# trimsir_me12 register map
Registers are read-write, no defined reset value unless marked. A register's access mark holds for its fields unless they carry their own. Offsets are from the block's base; lines under a group give offsets from that group; [hi:lo] are bit positions; {n}, {i} and the like mark numbered series; 'fields as' and 'values as' point back to an identical list; <NAME> marks a mode.

## Memory map
0x40005400 TRIMSIR size 0x400 — Trim System Initilazation Registers

## TRIMSIR — Trim System Initilazation Registers
Base 0x40005400
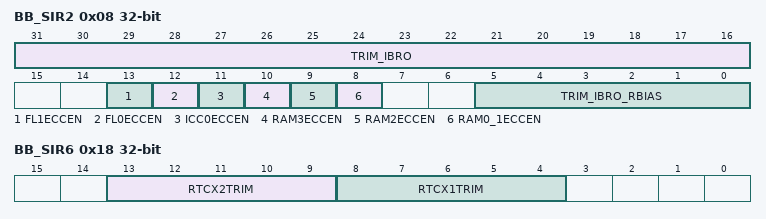
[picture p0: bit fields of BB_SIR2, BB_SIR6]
0x08 BB_SIR2 — System Init. Configuration Register 2.
  [31:16] TRIM_IBRO — HIRC8M Trim
  [13] FL1ECCEN — Flash 1 ECC Enable
    0=dis (ECC Disabled.); 1=en (ECC Enabled.)
  [12] FL0ECCEN — Flash 0 ECC Enable
    0=dis (ECC Disabled.); 1=en (ECC Enabled.)
  [11] ICC0ECCEN — ICC 0 ECC Enable
    0=dis (ECC Disabled.); 1=en (ECC Enabled.)
  [10] RAM3ECCEN — RAM 3 ECC Enable
    0=dis (ECC Disabled.); 1=en (ECC Enabled.)
  [9] RAM2ECCEN — RAM 2 ECC Enable
    0=dis (ECC Disabled.); 1=en (ECC Enabled.)
  [8] RAM0_1ECCEN — RAM 0 and RAM 1 ECC Enable
    0=dis (ECC Disabled.); 1=en (ECC Enabled.)
  [5:0] TRIM_IBRO_RBIAS — HIRC8M Trim
0x0C BB_SIR3 — System Init. Configuration Register 3.
0x18 BB_SIR6 ro — System Init. Configuration Register 6.
  [13:9] RTCX2TRIM, [8:4] RTCX1TRIM
